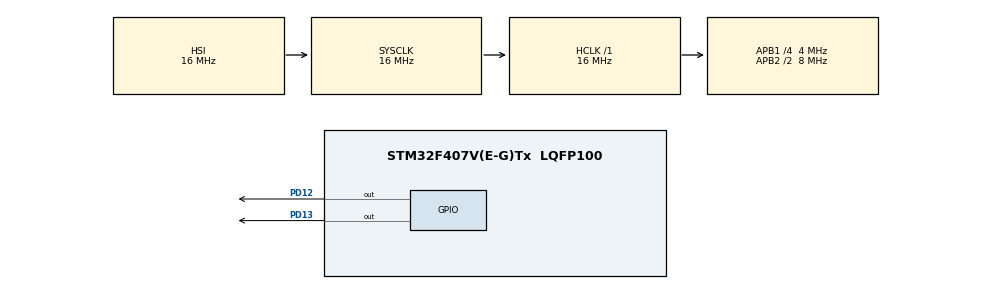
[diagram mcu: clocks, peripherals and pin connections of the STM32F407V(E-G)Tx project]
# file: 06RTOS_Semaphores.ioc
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FREERTOS.BinarySemaphores01=BinarySem,Dynamic,NULL,Available
FREERTOS.Tasks01=SendTask,0,128,StartSendTask,Default,NULL,Dynamic,NULL,NULL;Rx_data,-3,128,StartReceive02,Default,NULL,Dynamic,NULL,NULL
Mcu.Family=STM32F4
Mcu.Name=STM32F407V(E-G)Tx
Mcu.Package=LQFP100
NVIC.PriorityGroup=NVIC_PRIORITYGROUP_4
NVIC.TIM6_DAC_IRQn=true\:15\:0\:false\:false\:true\:false\:false\:true\:true
NVIC.TimeBase=TIM6_DAC_IRQn
NVIC.TimeBaseIP=TIM6
PD12.Signal=GPIO_Output
PD13.Signal=GPIO_Output
ProjectManager.HeapSize=0x200
ProjectManager.StackSize=0x400
ProjectManager.TargetToolchain=STM32CubeIDE
RCC.48MHZClocksFreq_Value=96000000
RCC.AHBFreq_Value=16000000
RCC.APB1CLKDivider=RCC_HCLK_DIV4
RCC.APB1Freq_Value=4000000
RCC.APB1TimFreq_Value=8000000
RCC.APB2CLKDivider=RCC_HCLK_DIV2
RCC.APB2Freq_Value=8000000
RCC.APB2TimFreq_Value=16000000
RCC.CortexFreq_Value=16000000
RCC.HCLKFreq_Value=16000000
RCC.HSE_VALUE=8000000
RCC.HSI_VALUE=16000000
RCC.PLLM=8
RCC.PLLN=336
RCC.PLLQ=7
RCC.SYSCLKFreq_VALUE=16000000
RCC.VCOOutputFreq_Value=672000000
VP_FREERTOS_VS_CMSIS_V1.Mode=CMSIS_V1
VP_SYS_VS_tim6.Mode=TIM6
board=STM32F407G-DISC1

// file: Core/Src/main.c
/* USER CODE BEGIN Header */
/**
  ******************************************************************************
  * @file           : main.c
  * @brief          : Main program body
  ******************************************************************************
  * @attention
  *
  * Copyright (c) 2026 STMicroelectronics.
  * All rights reserved.
  *
  * This software is licensed under terms that can be found in the LICENSE file
  * in the root directory of this software component.
  * If no LICENSE file comes with this software, it is provided AS-IS.
  *
  ******************************************************************************
  */
/* USER CODE END Header */
#include "main.h"
#include "cmsis_os.h"

osThreadId SendTaskHandle;
osThreadId Rx_dataHandle;
osSemaphoreId BinarySemHandle;

void SystemClock_Config(void);
static void MX_GPIO_Init(void);
void StartSendTask(void const * argument);
void StartReceive02(void const * argument);

int main(void)
{

  /* MCU Configuration--------------------------------------------------------*/

  /* Reset of all peripherals, Initializes the Flash interface and the Systick. */
  HAL_Init();

  /* Configure the system clock */
  SystemClock_Config();

  /* Initialize all configured peripherals */
  MX_GPIO_Init();

  /* Create the semaphores(s) */
  /* definition and creation of BinarySem */
  osSemaphoreDef(BinarySem);
  BinarySemHandle = osSemaphoreCreate(osSemaphore(BinarySem), 1);

  /* Create the thread(s) */
  /* definition and creation of SendTask */
  osThreadDef(SendTask, StartSendTask, osPriorityNormal, 0, 128);
  SendTaskHandle = osThreadCreate(osThread(SendTask), NULL);

  /* definition and creation of Rx_data */
  osThreadDef(Rx_data, StartReceive02, osPriorityIdle, 0, 128);
  Rx_dataHandle = osThreadCreate(osThread(Rx_data), NULL);

  /* Start scheduler */
  osKernelStart();

  /* We should never get here as control is now taken by the scheduler */

  /* Infinite loop */
  while (1)
  {

  }
}

void SystemClock_Config(void)
{
  RCC_OscInitTypeDef RCC_OscInitStruct = {0};
  RCC_ClkInitTypeDef RCC_ClkInitStruct = {0};

  /** Configure the main internal regulator output voltage
  */
  __HAL_RCC_PWR_CLK_ENABLE();
  __HAL_PWR_VOLTAGESCALING_CONFIG(PWR_REGULATOR_VOLTAGE_SCALE1);

  /** Initializes the RCC Oscillators according to the specified parameters
  * in the RCC_OscInitTypeDef structure.
  */
  RCC_OscInitStruct.OscillatorType = RCC_OSCILLATORTYPE_HSI;
  RCC_OscInitStruct.HSIState = RCC_HSI_ON;
  RCC_OscInitStruct.HSICalibrationValue = RCC_HSICALIBRATION_DEFAULT;
  RCC_OscInitStruct.PLL.PLLState = RCC_PLL_NONE;
  if (HAL_RCC_OscConfig(&RCC_OscInitStruct) != HAL_OK)
  {
    Error_Handler();
  }

  /** Initializes the CPU, AHB and APB buses clocks
  */
  RCC_ClkInitStruct.ClockType = RCC_CLOCKTYPE_HCLK|RCC_CLOCKTYPE_SYSCLK
                              |RCC_CLOCKTYPE_PCLK1|RCC_CLOCKTYPE_PCLK2;
  RCC_ClkInitStruct.SYSCLKSource = RCC_SYSCLKSOURCE_HSI;
  RCC_ClkInitStruct.AHBCLKDivider = RCC_SYSCLK_DIV1;
  RCC_ClkInitStruct.APB1CLKDivider = RCC_HCLK_DIV4;
  RCC_ClkInitStruct.APB2CLKDivider = RCC_HCLK_DIV2;

  if (HAL_RCC_ClockConfig(&RCC_ClkInitStruct, FLASH_LATENCY_0) != HAL_OK)
  {
    Error_Handler();
  }
}

static void MX_GPIO_Init(void)
{
  GPIO_InitTypeDef GPIO_InitStruct = {0};

  /* GPIO Ports Clock Enable */
  __HAL_RCC_GPIOD_CLK_ENABLE();

  /*Configure GPIO pin Output Level */
  HAL_GPIO_WritePin(GPIOD, GPIO_PIN_12|GPIO_PIN_13, GPIO_PIN_RESET);

  /*Configure GPIO pins : PD12 PD13 */
  GPIO_InitStruct.Pin = GPIO_PIN_12|GPIO_PIN_13;
  GPIO_InitStruct.Mode = GPIO_MODE_OUTPUT_PP;
  GPIO_InitStruct.Pull = GPIO_NOPULL;
  GPIO_InitStruct.Speed = GPIO_SPEED_FREQ_LOW;
  HAL_GPIO_Init(GPIOD, &GPIO_InitStruct);

}

void StartSendTask(void const * argument)
{
  /* USER CODE BEGIN 5 */
  /* Infinite loop */
  for(;;)
  {
	  osSemaphoreRelease(BinarySemHandle);
    osDelay(1000);
  }
  /* USER CODE END 5 */
}

void StartReceive02(void const * argument)
{
  /* USER CODE BEGIN StartReceive02 */
  /* Infinite loop */
  for(;;)
  {
	  if(osSemaphoreWait(BinarySemHandle, osWaitForever) == osOK)
		  HAL_GPIO_TogglePin(GPIOD, GPIO_PIN_12);

	  if(osSemaphoreWait(BinarySemHandle, osWaitForever) != osOK)
    	  HAL_GPIO_TogglePin(GPIOD, GPIO_PIN_13);
  }
  /* USER CODE END StartReceive02 */
}

void HAL_TIM_PeriodElapsedCallback(TIM_HandleTypeDef *htim)
{
  if (htim->Instance == TIM6)
  {
    HAL_IncTick();
  }
}

void Error_Handler(void)
{
  __disable_irq();
  while (1)
  {
  }
}
